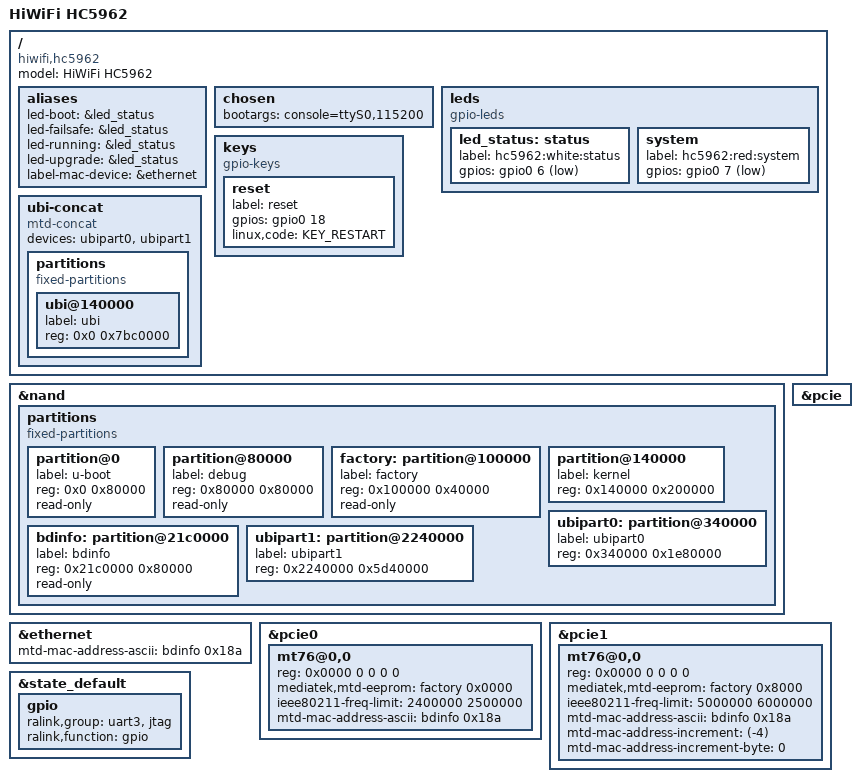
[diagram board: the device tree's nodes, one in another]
/dts-v1/;

#include "mt7621.dtsi"

#include <dt-bindings/gpio/gpio.h>
#include <dt-bindings/input/input.h>

/ {
	compatible = "hiwifi,hc5962", "mediatek,mt7621-soc";
	model = "HiWiFi HC5962";

	aliases {
		led-boot = &led_status;
		led-failsafe = &led_status;
		led-running = &led_status;
		led-upgrade = &led_status;
		label-mac-device = &ethernet;
	};

	chosen {
		bootargs = "console=ttyS0,115200";
	};

	leds {
		compatible = "gpio-leds";

		led_status: status {
			label = "hc5962:white:status";
			gpios = <&gpio0 6 GPIO_ACTIVE_LOW>;
		};

		system {
			label = "hc5962:red:system";
			gpios = <&gpio0 7 GPIO_ACTIVE_LOW>;
		};
	};

	keys {
		compatible = "gpio-keys";

		reset {
			label = "reset";
			gpios = <&gpio0 18 GPIO_ACTIVE_HIGH>;
			linux,code = <KEY_RESTART>;
		};
	};

	ubi-concat {
		compatible = "mtd-concat";
		devices = <&ubipart0 &ubipart1>;

		partitions {
			compatible = "fixed-partitions";
			#address-cells = <1>;
			#size-cells = <1>;

			ubi@140000 {
				label = "ubi";
				reg = <0x0 0x7bc0000>;
			};
		};
	};
};

&nand {
	status = "okay";

	partitions {
		compatible = "fixed-partitions";
		#address-cells = <1>;
		#size-cells = <1>;

		partition@0 {
			label = "u-boot";
			reg = <0x0 0x80000>;
			read-only;
		};

		partition@80000 {
			label = "debug";
			reg = <0x80000 0x80000>;
			read-only;
		};

		factory: partition@100000 {
			label = "factory";
			reg = <0x100000 0x40000>;
			read-only;
		};

		partition@140000 {
			label = "kernel";
			reg = <0x140000 0x200000>;
		};

		ubipart0: partition@340000 {
			label = "ubipart0";
			reg = <0x340000 0x1e80000>;
		};

		bdinfo: partition@21c0000 {
			label = "bdinfo";
			reg = <0x21c0000 0x80000>;
			read-only;
		};

		ubipart1: partition@2240000 {
			label = "ubipart1";
			reg = <0x2240000 0x5d40000>;
		};
	};
};

&ethernet {
	mtd-mac-address-ascii = <&bdinfo 0x18a>;
};

&pcie {
	status = "okay";
};

&pcie0 {
	mt76@0,0 {
		reg = <0x0000 0 0 0 0>;
		mediatek,mtd-eeprom = <&factory 0x0000>;
		ieee80211-freq-limit = <2400000 2500000>;
		mtd-mac-address-ascii = <&bdinfo 0x18a>;
	};
};

&pcie1 {
	mt76@0,0 {
		reg = <0x0000 0 0 0 0>;
		mediatek,mtd-eeprom = <&factory 0x8000>;
		ieee80211-freq-limit = <5000000 6000000>;
		mtd-mac-address-ascii = <&bdinfo 0x18a>;
		mtd-mac-address-increment = <(-4)>;
		mtd-mac-address-increment-byte = <0>;
	};
};

&state_default {
	gpio {
		ralink,group = "uart3", "jtag";
		ralink,function = "gpio";
	};
};
